AUTOSAR XML (schema 4-0-3)
package /BswM/ServiceSwComponentTypes
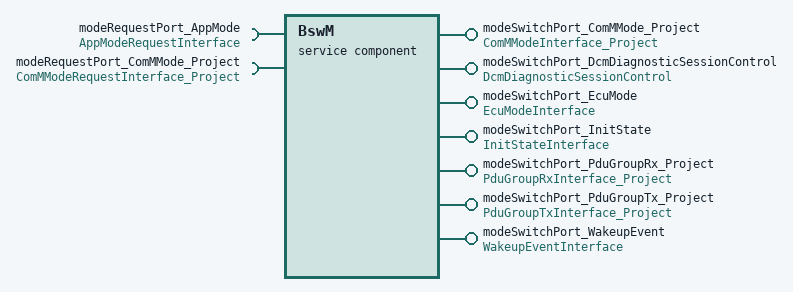
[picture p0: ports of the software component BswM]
  service sw component type BswM
    require port modeRequestPort_AppMode: nonqueued-receiver-com-spec=AppMode, required-interface=AppModeRequestInterface
    require port modeRequestPort_ComMMode_Project: nonqueued-receiver-com-spec=ComMMode_Project, required-interface=ComMModeRequestInterface_Project
    7 x provide port:
      modeSwitchPort_ComMMode_Project: mode-switch-sender-com-spec{enhanced-mode-api=false, mode-group=ComMMode_Project, queue-length=1}, provided-interface=ComMModeInterface_Project
      modeSwitchPort_DcmDiagnosticSessionControl: mode-switch-sender-com-spec{enhanced-mode-api=false, mode-group=DcmDiagnosticSessionControl, queue-length=1}, provided-interface=DcmDiagnosticSessionControl
      modeSwitchPort_EcuMode: mode-switch-sender-com-spec{enhanced-mode-api=false, mode-group=EcuMode, queue-length=1}, provided-interface=EcuModeInterface
      modeSwitchPort_InitState: mode-switch-sender-com-spec{enhanced-mode-api=false, mode-group=InitState, queue-length=1}, provided-interface=InitStateInterface
      modeSwitchPort_PduGroupRx_Project: mode-switch-sender-com-spec{enhanced-mode-api=false, mode-group=PduGroupRx_Project, queue-length=1}, provided-interface=PduGroupRxInterface_Project
      modeSwitchPort_PduGroupTx_Project: mode-switch-sender-com-spec{enhanced-mode-api=false, mode-group=PduGroupTx_Project, queue-length=1}, provided-interface=PduGroupTxInterface_Project
      modeSwitchPort_WakeupEvent: mode-switch-sender-com-spec{enhanced-mode-api=false, mode-group=WakeupEvent, queue-length=1}, provided-interface=WakeupEventInterface
    behavior SwcIB_BswM: data-type-mapping=[MAP_AppMode, MAP_ComMMode], handle-termination-and-restart=NO-SUPPORT
      data received event DRE_BswM_Immediate_SwcModeRequest_AppMode_modeRequestPort_AppMode_AppMode: start-on-event=BswM_Immediate_SwcModeRequest_AppMode, data=modeRequestPort_AppMode.AppMode
      data received event DRE_BswM_Immediate_SwcModeRequest_ComMMode_Project_modeRequestPort_ComMMode_Project_ComMMode_Project: start-on-event=BswM_Immediate_SwcModeRequest_ComMMode_Project, data=modeRequestPort_ComMMode_Project.ComMMode_Project
      9 x runnable:
        BswM_ActionList_RteSwitch_ComMMode_Project: can-be-invoked-concurrently=true
          mode switch point MSP_BswM_ActionList_RteSwitch_ComMMode_Project_modeSwitchPort_ComMMode_Project_ComMMode_Project: category=TOOL_CONFIGURED, mode-group=modeSwitchPort_ComMMode_Project.ComMMode_Project
        BswM_ActionList_RteSwitch_DcmDiagnosticSessionControl: can-be-invoked-concurrently=true
          mode switch point MSP_BswM_ActionList_RteSwitch_DcmDiagnosticSessionControl_modeSwitchPort_DcmDiagnosticSessionControl_DcmDiagnosticSessionControl: category=TOOL_CONFIGURED, mode-group=modeSwitchPort_DcmDiagnosticSessionControl.DcmDiagnosticSessionControl
        BswM_ActionList_RteSwitch_EcuMode: can-be-invoked-concurrently=true
          mode switch point MSP_BswM_ActionList_RteSwitch_EcuMode_modeSwitchPort_EcuMode_EcuMode: category=TOOL_CONFIGURED, mode-group=modeSwitchPort_EcuMode.EcuMode
        BswM_ActionList_RteSwitch_InitState: can-be-invoked-concurrently=true
          mode switch point MSP_BswM_ActionList_RteSwitch_InitState_modeSwitchPort_InitState_InitState: category=TOOL_CONFIGURED, mode-group=modeSwitchPort_InitState.InitState
        BswM_ActionList_RteSwitch_PduGroupRx_Project: can-be-invoked-concurrently=true
          mode switch point MSP_BswM_ActionList_RteSwitch_PduGroupRx_Project_modeSwitchPort_PduGroupRx_Project_PduGroupRx_Project: category=TOOL_CONFIGURED, mode-group=modeSwitchPort_PduGroupRx_Project.PduGroupRx_Project
        BswM_ActionList_RteSwitch_PduGroupTx_Project: can-be-invoked-concurrently=true
          mode switch point MSP_BswM_ActionList_RteSwitch_PduGroupTx_Project_modeSwitchPort_PduGroupTx_Project_PduGroupTx_Project: category=TOOL_CONFIGURED, mode-group=modeSwitchPort_PduGroupTx_Project.PduGroupTx_Project
        BswM_ActionList_RteSwitch_WakeupEvent: can-be-invoked-concurrently=true
          mode switch point MSP_BswM_ActionList_RteSwitch_WakeupEvent_modeSwitchPort_WakeupEvent_WakeupEvent: category=TOOL_CONFIGURED, mode-group=modeSwitchPort_WakeupEvent.WakeupEvent
        BswM_Immediate_SwcModeRequest_AppMode
          data-receive-point-by-arguments:
            access DRPBA_BswM_Immediate_SwcModeRequest_AppMode_modeRequestPort_AppMode_AppMode: category=TOOL_CONFIGURED, accessed-variable=modeRequestPort_AppMode.AppMode.AppMode
        BswM_Immediate_SwcModeRequest_ComMMode_Project
          data-receive-point-by-arguments:
            access DRPBA_BswM_Immediate_SwcModeRequest_ComMMode_Project_modeRequestPort_ComMMode_Project_ComMMode_Project: category=TOOL_CONFIGURED, accessed-variable=modeRequestPort_ComMMode_Project.ComMMode_Project.ComMMode_Project
  swc implementation SwcImplementation_BswM: programming-language=C, swc-bsw-mapping=SwcBswMapping_BswM, behavior=SwcIB_BswM
package /BswM/SwcBswMappings
  swc bsw mapping SwcBswMapping_BswM: bsw-behavior=BswIB_BswM, swc-behavior=SwcIB_BswM
